# WKUP_CTRL_MMR0_WKUP_CTRL_MMR0_BOOT_MMRS_43010000h register map
Vendor: Texas Instruments
Peripheral module from a debugger description file (folder am62L).
Registers are 32-bit, read-only, reset 0x0 unless marked. A register's access mark holds for its fields unless they carry their own. Offsets are as the file gives them; lines under a group give offsets from that group; [hi:lo] are bit positions; {n}, {i} and the like mark numbered series; 'fields as' and 'values as' point back to an identical list; <NAME> marks a mode.

## WKUP_CTRL_MMR0_BOOT_MMRS
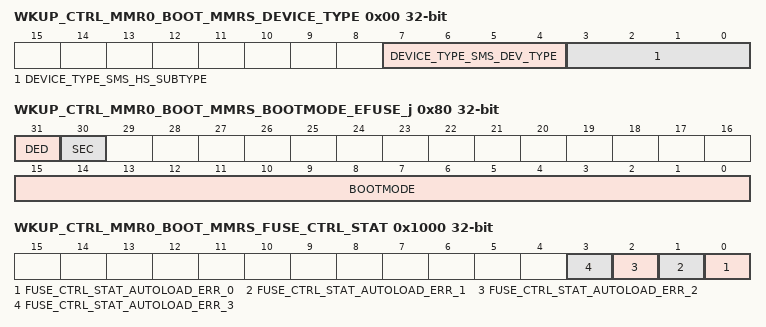
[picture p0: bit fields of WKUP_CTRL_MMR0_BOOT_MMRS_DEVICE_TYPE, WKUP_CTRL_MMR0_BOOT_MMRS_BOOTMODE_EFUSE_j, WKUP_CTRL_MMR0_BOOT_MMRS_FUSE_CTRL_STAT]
0x00 WKUP_CTRL_MMR0_BOOT_MMRS_DEVICE_TYPE — Device Type as Decoded by SMS
  [7:4] DEVICE_TYPE_SMS_DEV_TYPE — Type of device reported by SMS. Values not listed should be interpreted as BAD. 3 DT_GP5 DT_TEST9 DT_EMU10 DT_HS
  [3:0] DEVICE_TYPE_SMS_HS_SUBTYPE — Device Subtype Reported by SMS Reset Source: mod_por_rst_n
0x30 WKUP_CTRL_MMR0_BOOT_MMRS_DEVSTAT rw — Indicates SoC bootstrap selection. (RW Versions) This register latches the SoC bootstrap pins on the deassertion of power on reset, but unlike MAIN_BOOTCFG it can be overwritten after the initial boot. Note that bootstrap pins are not relatched during exit from Deepsleep because this register is isolated from MAIN domain resets during DeepSleep.
  [15:0] DEVSTAT_BOOTMODE — Specifies the device Primary and Backup boot media. Reset Source: mod_por_rst_n
0x34 WKUP_CTRL_MMR0_BOOT_MMRS_BOOTCFG — Indicates SoC bootstrap selection. (Read Only) This register latches the SoC bootstrap pins on the deassertion of power on reset. Unlike MAIN_DEVSTAT, this register is read only and always reflects the latched value. Note that bootstrap pins are not relatched during exit from Deepsleep because this register is isolated from MAIN domain resets during DeepSleep.
  [15:0] BOOTCFG_BOOTMODE — Specifies the device Primary and Backup boot media as latched at PORz Reset Source: mod_por_rst_n
0x44 WKUP_CTRL_MMR0_BOOT_MMRS_BOOT_PROGRESS rw — Used by ROM to mark the progress of the boot operation
  [31:0] BOOT_PROGRESS_PROGRESS — Written by ROM to indicate boot progression. Values and their meaning are determined by the ROM. Reset Source: mod_por_rst_n
0x80 WKUP_CTRL_MMR0_BOOT_MMRS_BOOTMODE_EFUSE_j — Corrected (SECDED) value of EFUSE0 Boot Mode
  [31] DED — For Debug - SECDED Detected a Double Bit Error in bootmode 0 value or in the stored parity bits. Reset Source: mod_por_rst_n
  [30] SEC — For Debug - SECDED Corrected a Single Bit Error in bootmode 0 value or in the stored parity bits. Reset Source: mod_por_rst_n
  [15:0] BOOTMODE — For Debug - SECDED Corrected value of efuse bootmode 0 value Reset Source: mod_por_rst_n
0xA0 WKUP_CTRL_MMR0_BOOT_MMRS_BOOTMODE_EFUSE_RAW_j — Uncorrected (SECDED) value of EFUSE0 Boot Mode
  [24:0] BOOTMODE — For Debug - Raw Uncorrected value of efuse bootmode 0 value Reset Source: mod_por_rst_n
0xB0 WKUP_CTRL_MMR0_BOOT_MMRS_BOOTMODE_PINS_RAW — Bootmode Pins Captured on PORz Rising Edge
  [15:0] BOOTMODE_PINS_RAW_BOOTMODE — For Debug - Bootmode pin values latched on rising edge of PORz Reset Source: mod_por_rst_n
0x1000 WKUP_CTRL_MMR0_BOOT_MMRS_FUSE_CTRL_STAT — Indicates Error Status detected by the Main EFUSE Controller
  [n] FUSE_CTRL_STAT_AUTOLOAD_ERR_{n} (n=0..3) — Autoload Error Status Chain {n} 0 NO_ERROR1 ERROR
0x1020 WKUP_CTRL_MMR0_BOOT_MMRS_FUSE_CRC_STAT — Indicates status of fuse chain CRC
  [1] FUSE_CRC_STAT_CRC_ERR_1 — Indicates eFuse CRC error on chain 1 0 NO_ERROR1 ERROR
0x1104 WKUP_CTRL_MMR0_BOOT_MMRS_CHAIN1_CRC_CALC rw — Indicates the calculated CRC for MAIN fuse chain 1
  [31:0] CHAIN1_CRC_CALC_CRC — Calculated chain CRC Reset Source: mod_por_rst_n
0x1204 WKUP_CTRL_MMR0_BOOT_MMRS_CHAIN1_CRC_CALC_RO — Reads the calculated chain, updated after deep sleep exit (read only)
  [31:0] CHAIN1_CRC_CALC_RO_CRC — Read only view of Stored CRC Chain Reset Source: mod_por_rst_n
0x1304 WKUP_CTRL_MMR0_BOOT_MMRS_CHAIN1_CRC_FUSE — Indicates the stored CRC for MAIN fuse chain 1
  [31:0] CHAIN1_CRC_FUSE_CRC — Stored chain CRC Reset Source: mod_por_rst_n
